# R7FA6M5BH register map
Vendor: Renesas Electronics Corporation; Series: RA6; File version: 1.20.01
CPU: CM33 r0p4, little endian, MPU, FPU, VTOR, 4 interrupt priority bits, 96 interrupts
Registers are 32-bit, read-write, reset 0x0 unless marked. A register's access mark holds for its fields unless they carry their own. Offsets are from the block's base; [hi:lo] are bit positions; 'fields as' and 'values as' point back to an identical list.

## MSTP — Module Stop Control
Base 0x40084000
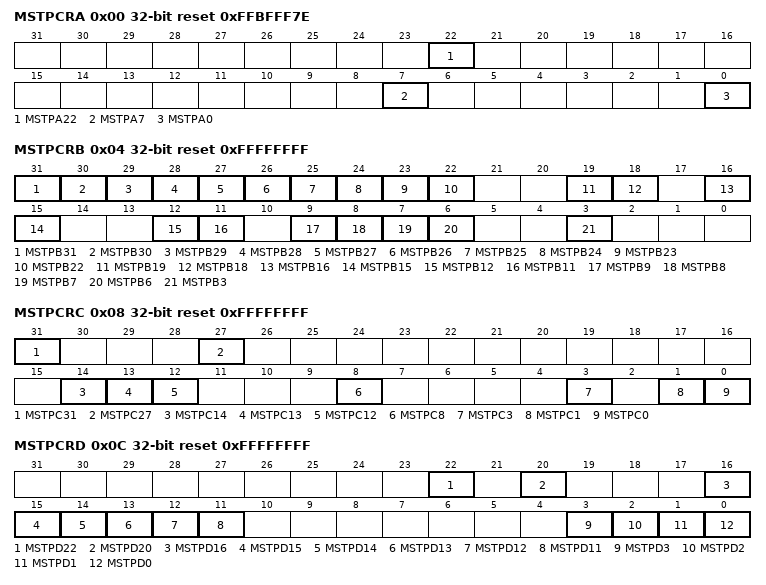
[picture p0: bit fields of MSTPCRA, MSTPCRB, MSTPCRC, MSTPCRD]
0x00 MSTPCRA reset 0xFFBFFF7E — Module Stop Control Register A
  [all] fields
    0=Cancel the module-stop state; 1=Enter the module-stop state
  [22] MSTPA22 — DMA Controller/Data Transfer Controller Module Stop
  [7] MSTPA7 — Standby SRAM Module Stop
  [0] MSTPA0 — SRAM0 Module Stop
0x04 MSTPCRB reset 0xFFFFFFFF — Module Stop Control Register B
  [all] fields
    values as the fields of MSTPCRA
  [31] MSTPB31 — Serial Communication Interface 0 Module Stop
  [30] MSTPB30 — Serial Communication Interface 1 Module Stop
  [29] MSTPB29 — Serial Communication Interface 2 Module Stop
  [28] MSTPB28 — Serial Communication Interface 3 Module Stop
  [27] MSTPB27 — Serial Communication Interface 4 Module Stop
  [26] MSTPB26 — Serial Communication Interface 5 Module Stop
  [25] MSTPB25 — Serial Communication Interface 6 Module Stop
  [24] MSTPB24 — Serial Communication Interface 7 Module Stop
  [23] MSTPB23 — Serial Communication Interface 8 Module Stop
  [22] MSTPB22 — Serial Communication Interface 9 Module Stop
  [19] MSTPB19 — Serial Peripheral Interface 0 Module Stop
  [18] MSTPB18 — Serial Peripheral Interface 1 Module Stop
  [16] MSTPB16 — OSPI Module Stop
  [15] MSTPB15 — ETHERC0 and EDMAC0 Module Stop
  [12] MSTPB12 — Universal Serial Bus 2.0 HS Interface Module Stop
  [11] MSTPB11 — Universal Serial Bus 2.0 FS Interface 0 Module Stop
  [9] MSTPB9 — I2C Bus Interface 0 Module Stop
  [8] MSTPB8 — I2C Bus Interface 1 Module Stop
  [7] MSTPB7 — I2C Bus Interface 2 Module Stop
  [6] MSTPB6 — Quad Serial Peripheral Interface Module Stop
  [3] MSTPB3 — CEC Module Stop
0x08 MSTPCRC reset 0xFFFFFFFF — Module Stop Control Register C
  [all] fields
    values as the fields of MSTPCRA
  [31] MSTPC31 — SCE9 Module Stop
  [27] MSTPC27 — CANFD Module Stop
  [14] MSTPC14 — Event Link Controller Module Stop
  [13] MSTPC13 — Data Operation Circuit Module Stop
  [12] MSTPC12 — Secure Digital HOST IF / Multi Media Card 0 Module Stop
  [8] MSTPC8 — Serial Sound Interface Enhanced Module Stop
  [3] MSTPC3 — Capacitive Touch Sensing Unit Module Stop
  [1] MSTPC1 — Cyclic Redundancy Check Calculator Module Stop
  [0] MSTPC0 — Clock Frequency Accuracy Measurement Circuit Module Stop
0x0C MSTPCRD reset 0xFFFFFFFF — Module Stop Control Register D
  [all] fields
    values as the fields of MSTPCRA
  [22] MSTPD22 — Temperature Sensor Module Stop
  [20] MSTPD20 — 12-bit D/A Converter Module Stop
  [16] MSTPD16 — 12-bit A/D Converter 0 Module Stop
  [15] MSTPD15 — 12-bit A/D Converter 1 Module Stop
  [14] MSTPD14 — Port Output Enable for GPT Group A Module Stop
  [13] MSTPD13 — Port Output Enable for GPT Group B Module Stop
  [12] MSTPD12 — Port Output Enable for GPT Group C Module Stop
  [11] MSTPD11 — Port Output Enable for GPT Group D Module Stop
  [3] MSTPD3 — Low Power Asynchronous General Purpose Timer 0 Module Stop
  [2] MSTPD2 — Low Power Asynchronous General Purpose Timer 1 Module Stop
  [1] MSTPD1 — Low Power Asynchronous General Purpose Timer 2 Module Stop
  [0] MSTPD0 — Low Power Asynchronous General Purpose Timer 3 Module Stop
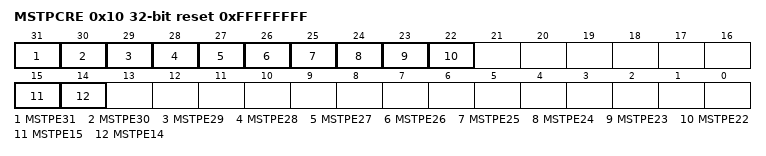
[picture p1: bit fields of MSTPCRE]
0x10 MSTPCRE reset 0xFFFFFFFF — Module Stop Control Register E
  [all] fields
    values as the fields of MSTPCRA
  [31] MSTPE31 — GPT0 Module Stop
  [30] MSTPE30 — GPT1 Module Stop
  [29] MSTPE29 — GPT2 Module Stop
  [28] MSTPE28 — GPT3 Module Stop
  [27] MSTPE27 — GPT4 Module Stop
  [26] MSTPE26 — GPT5 Module Stop
  [25] MSTPE25 — GPT6 Module Stop
  [24] MSTPE24 — GPT7 Module Stop
  [23] MSTPE23 — GPT8 Module Stop
  [22] MSTPE22 — GPT9 Module Stop
  [15] MSTPE15 — Low Power Asynchronous General Purpose Timer 4 Module Stop
  [14] MSTPE14 — Low Power Asynchronous General Purpose Timer 5 Module Stop
